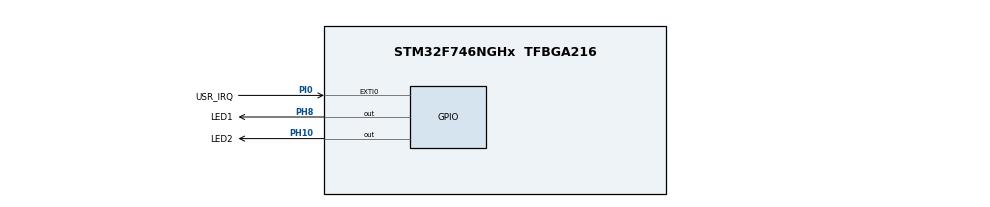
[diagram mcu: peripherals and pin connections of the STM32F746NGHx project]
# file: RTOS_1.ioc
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FREERTOS.BinarySemaphores01=BinarySemaphore01,Dynamic,NULL
FREERTOS.INCLUDE_vTaskDelayUntil=1
FREERTOS.Tasks01=Task1,0,128,StartTask1,Default,NULL,Dynamic,NULL,NULL;Task2,1,128,StartTask02,Default,NULL,Dynamic,NULL,NULL
Mcu.Family=STM32F7
Mcu.Name=STM32F746NGHx
Mcu.Package=TFBGA216
NVIC.EXTI0_IRQn=true\:5\:0\:false\:false\:true\:true\:true\:true\:true
NVIC.PriorityGroup=NVIC_PRIORITYGROUP_4
PA13.Mode=JTAG_5_pins
PA13.Signal=SYS_JTMS-SWDIO
PA14.Mode=JTAG_5_pins
PA14.Signal=SYS_JTCK-SWCLK
PA15.Mode=JTAG_5_pins
PA15.Signal=SYS_JTDI
PB3.Mode=JTAG_5_pins
PB3.Signal=SYS_JTDO-SWO
PB4.Mode=JTAG_5_pins
PB4.Signal=SYS_JTRST
PH0/OSC_IN.Mode=HSE-External-Oscillator
PH0/OSC_IN.Signal=RCC_OSC_IN
PH1/OSC_OUT.Mode=HSE-External-Oscillator
PH1/OSC_OUT.Signal=RCC_OSC_OUT
PH10.GPIO_Label=LED2
PH10.GPIO_ModeDefaultOutputPP=GPIO_MODE_OUTPUT_PP
PH10.GPIO_PuPd=GPIO_PULLDOWN
PH10.Signal=GPIO_Output
PH8.GPIO_Label=LED1
PH8.GPIO_PuPd=GPIO_PULLDOWN
PH8.Signal=GPIO_Output
PI0.GPIO_Label=USR_IRQ
PI0.GPIO_ModeDefaultEXTI=GPIO_MODE_IT_RISING_FALLING
PI0.Signal=GPXTI0
ProjectManager.HeapSize=0x200
ProjectManager.StackSize=0x400
ProjectManager.TargetToolchain=STM32CubeIDE
RCC.HSE_VALUE=25000000
RCC.HSI_VALUE=16000000
RCC.LSE_VALUE=32768
RCC.USBFreq_Value=96000000
RCC.VCOOutputFreq_Value=192000000
VP_FREERTOS_VS_CMSIS_V1.Mode=CMSIS_V1
board=custom

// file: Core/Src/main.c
/* USER CODE BEGIN Header */
/**
  ******************************************************************************
  * @file           : main.c
  * @brief          : Main program body
  ******************************************************************************
  * @attention
  *
  * Copyright (c) 2023 STMicroelectronics.
  * All rights reserved.
  *
  * This software is licensed under terms that can be found in the LICENSE file
  * in the root directory of this software component.
  * If no LICENSE file comes with this software, it is provided AS-IS.
  *
  ******************************************************************************
  */
/* USER CODE END Header */
#include "main.h"
#include "cmsis_os.h"

osThreadId Task1Handle;
osThreadId Task2Handle;
osSemaphoreId BinarySemaphore01Handle;

void SystemClock_Config(void);
static void MX_GPIO_Init(void);
void StartTask1(void const * argument);
void StartTask02(void const * argument);

int main(void)
{

  /* MCU Configuration--------------------------------------------------------*/

  /* Reset of all peripherals, Initializes the Flash interface and the Systick. */
  HAL_Init();

  /* Configure the system clock */
  SystemClock_Config();

  /* Initialize all configured peripherals */
  MX_GPIO_Init();

  /* Create the semaphores(s) */
  /* definition and creation of BinarySemaphore01 */
  osSemaphoreDef(BinarySemaphore01);
  BinarySemaphore01Handle = osSemaphoreCreate(osSemaphore(BinarySemaphore01), 1);

  /* Create the thread(s) */
  /* definition and creation of Task1 */
  osThreadDef(Task1, StartTask1, osPriorityNormal, 0, 128);
  Task1Handle = osThreadCreate(osThread(Task1), NULL);

  /* definition and creation of Task2 */
  osThreadDef(Task2, StartTask02, osPriorityAboveNormal, 0, 128);
  Task2Handle = osThreadCreate(osThread(Task2), NULL);

  /* Start scheduler */
  osKernelStart();
  /* We should never get here as control is now taken by the scheduler */
  /* Infinite loop */
  while (1)
  {

  }
}

void SystemClock_Config(void)
{
  RCC_OscInitTypeDef RCC_OscInitStruct = {0};
  RCC_ClkInitTypeDef RCC_ClkInitStruct = {0};

  /** Configure the main internal regulator output voltage
  */
  __HAL_RCC_PWR_CLK_ENABLE();
  __HAL_PWR_VOLTAGESCALING_CONFIG(PWR_REGULATOR_VOLTAGE_SCALE3);

  /** Initializes the RCC Oscillators according to the specified parameters
  * in the RCC_OscInitTypeDef structure.
  */
  RCC_OscInitStruct.OscillatorType = RCC_OSCILLATORTYPE_HSI;
  RCC_OscInitStruct.HSIState = RCC_HSI_ON;
  RCC_OscInitStruct.HSICalibrationValue = RCC_HSICALIBRATION_DEFAULT;
  RCC_OscInitStruct.PLL.PLLState = RCC_PLL_NONE;
  if (HAL_RCC_OscConfig(&RCC_OscInitStruct) != HAL_OK)
  {
    Error_Handler();
  }

  /** Initializes the CPU, AHB and APB buses clocks
  */
  RCC_ClkInitStruct.ClockType = RCC_CLOCKTYPE_HCLK|RCC_CLOCKTYPE_SYSCLK
                              |RCC_CLOCKTYPE_PCLK1|RCC_CLOCKTYPE_PCLK2;
  RCC_ClkInitStruct.SYSCLKSource = RCC_SYSCLKSOURCE_HSI;
  RCC_ClkInitStruct.AHBCLKDivider = RCC_SYSCLK_DIV1;
  RCC_ClkInitStruct.APB1CLKDivider = RCC_HCLK_DIV1;
  RCC_ClkInitStruct.APB2CLKDivider = RCC_HCLK_DIV1;

  if (HAL_RCC_ClockConfig(&RCC_ClkInitStruct, FLASH_LATENCY_0) != HAL_OK)
  {
    Error_Handler();
  }
}

static void MX_GPIO_Init(void)
{
  GPIO_InitTypeDef GPIO_InitStruct = {0};

  /* GPIO Ports Clock Enable */
  __HAL_RCC_GPIOB_CLK_ENABLE();
  __HAL_RCC_GPIOA_CLK_ENABLE();
  __HAL_RCC_GPIOI_CLK_ENABLE();
  __HAL_RCC_GPIOH_CLK_ENABLE();

  /*Configure GPIO pin Output Level */
  HAL_GPIO_WritePin(GPIOH, LED1_Pin|LED2_Pin, GPIO_PIN_RESET);

  /*Configure GPIO pin : USR_IRQ_Pin */
  GPIO_InitStruct.Pin = USR_IRQ_Pin;
  GPIO_InitStruct.Mode = GPIO_MODE_IT_RISING_FALLING;
  GPIO_InitStruct.Pull = GPIO_NOPULL;
  HAL_GPIO_Init(USR_IRQ_GPIO_Port, &GPIO_InitStruct);

  /*Configure GPIO pins : LED1_Pin LED2_Pin */
  GPIO_InitStruct.Pin = LED1_Pin|LED2_Pin;
  GPIO_InitStruct.Mode = GPIO_MODE_OUTPUT_PP;
  GPIO_InitStruct.Pull = GPIO_PULLDOWN;
  GPIO_InitStruct.Speed = GPIO_SPEED_FREQ_LOW;
  HAL_GPIO_Init(GPIOH, &GPIO_InitStruct);

  /* EXTI interrupt init*/
  HAL_NVIC_SetPriority(EXTI0_IRQn, 5, 0);
  HAL_NVIC_EnableIRQ(EXTI0_IRQn);

}

/* USER CODE BEGIN 4 */

void HAL_GPIO_EXTI_Callback(uint16_t GPIO_Pin)
{
	HAL_GPIO_WritePin(GPIOH, LED1_Pin, GPIO_PIN_RESET);
	osDelay(1000);
	HAL_GPIO_WritePin(GPIOH, LED1_Pin, GPIO_PIN_SET);

	osSemaphoreRelease(BinarySemaphore01Handle);
}

/* USER CODE END 4 */

void StartTask1(void const * argument)
{
  /* USER CODE BEGIN 5 */
  /* Infinite loop */

	//for( ; ; )
	//{
		/*HAL_GPIO_WritePin(GPIOH, LED1_Pin, GPIO_PIN_RESET);

		osDelay(500);

		HAL_GPIO_WritePin(GPIOH, LED1_Pin, GPIO_PIN_SET);

		osDelay(500);*/

		//osSemaphoreRelease(BinarySemaphore01Handle);
//	}
  /* USER CODE END 5 */
}

void StartTask02(void const * argument)
{
  /* USER CODE BEGIN StartTask02 */
  /* Infinite loop */

	for( ; ; )
	{
		osSemaphoreWait(BinarySemaphore01Handle, 2500);

		HAL_GPIO_WritePin(GPIOH, LED2_Pin, GPIO_PIN_SET);

	    osDelay(100);

	    HAL_GPIO_WritePin(GPIOH, LED2_Pin, GPIO_PIN_RESET);

	    osDelay(100);

	}
  /* USER CODE END StartTask02 */
}

void Error_Handler(void)
{
  __disable_irq();
  while (1)
  {
  }
}
